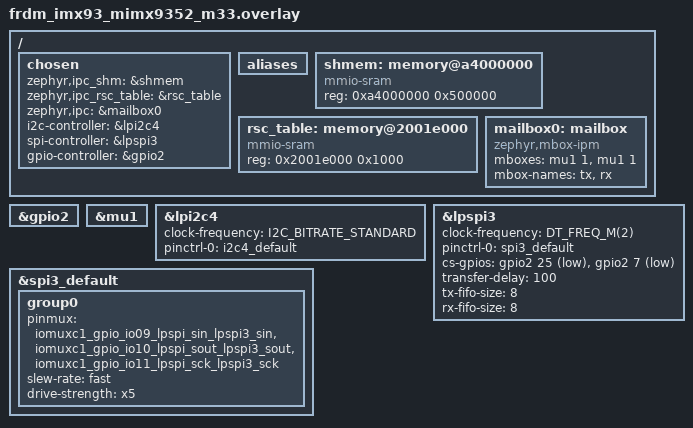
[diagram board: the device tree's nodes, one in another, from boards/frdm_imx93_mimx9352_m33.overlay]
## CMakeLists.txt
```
cmake_minimum_required(VERSION 3.20.0)
# Copyright (c) 2020 STMicroelectronics
#
# SPDX-License-Identifier: Apache-2.0
#

find_package(Zephyr REQUIRED HINTS $ENV{ZEPHYR_BASE})

project(multi_vdev)

target_include_directories(app PRIVATE ${LIBMETAL_INCLUDE_DIR} ${OPENAMP_INCLUDE_DIR} ${PLATFORM_DIR})

target_sources(app
        PRIVATE
        src/main.c
        src/resource_table.c
        src/addr_translation.c
        src/dev_virtio_can.c
        src/dev_virtio_entropy.c
        src/dev_virtio_gpio.c
        src/dev_virtio_i2c.c
        src/dev_virtio_spi.c
)
```

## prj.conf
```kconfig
CONFIG_KERNEL_BIN_NAME="zephyr_multi_vdev"
CONFIG_MAIN_STACK_SIZE=4096
CONFIG_HEAP_MEM_POOL_SIZE=8192

CONFIG_IPM=y
CONFIG_OPENAMP=y
CONFIG_OPENAMP_MASTER=n

CONFIG_GPIO=y
CONFIG_I2C=y
CONFIG_SPI=y
CONFIG_TEST_RANDOM_GENERATOR=y

CONFIG_SHELL=y
CONFIG_LOG=y
```

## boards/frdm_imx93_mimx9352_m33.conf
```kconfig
CONFIG_IPM_MBOX=y
CONFIG_MBOX_INIT_PRIORITY=0
CONFIG_SPI_COMPLETION_TIMEOUT_TOLERANCE=600
```

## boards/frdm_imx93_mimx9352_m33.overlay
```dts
/*
 * Copyright 2025 NXP
 *
 * SPDX-License-Identifier: Apache-2.0
 */

#include <zephyr/dt-bindings/i2c/i2c.h>
#include <zephyr/dt-bindings/gpio/gpio.h>

/ {
	chosen {
		/*
		 * shared memory reserved for the inter-processor communication
		 */
		zephyr,ipc_shm = &shmem;
		zephyr,ipc_rsc_table = &rsc_table;
		zephyr,ipc = &mailbox0;

		i2c-controller = &lpi2c4;
		spi-controller = &lpspi3;
		gpio-controller = &gpio2;
	};

	aliases {
		/delete-property/ led0;
		/delete-property/ led1;
		/delete-property/ sw0;
	};

	/delete-node/ leds;
	/delete-node/ keys;

	shmem: memory@a4000000 {
		compatible = "mmio-sram";
		reg = <0xa4000000 0x500000>;
	};

	rsc_table: memory@2001e000 {
		compatible = "mmio-sram";
		reg = <0x2001e000 0x1000>;
	};

	mailbox0: mailbox {
		compatible = "zephyr,mbox-ipm";
		mboxes = <&mu1 1>, <&mu1 1>;
		mbox-names = "tx", "rx";
		status = "okay";
	};
};

&gpio2 {
	status = "okay";
};

&mu1 {
	status = "okay";
};

&lpi2c4 {
	clock-frequency = <I2C_BITRATE_STANDARD>;
	pinctrl-0 = <&i2c4_default>;
	pinctrl-names = "default";
	status = "okay";
};

&spi3_default {
	// CS lines are driven as GPIOs, remove them from the spi3 pinmuxing
	group0 {
		pinmux = <&iomuxc1_gpio_io09_lpspi_sin_lpspi3_sin>,
			 <&iomuxc1_gpio_io10_lpspi_sout_lpspi3_sout>,
			 <&iomuxc1_gpio_io11_lpspi_sck_lpspi3_sck>;
		slew-rate = "fast";
		drive-strength = "x5";
	};
};

&lpspi3 {
	clock-frequency = <DT_FREQ_M(2)>;
	pinctrl-0 = <&spi3_default>;
	pinctrl-names = "default";
	cs-gpios = <&gpio2 25 GPIO_ACTIVE_LOW>, <&gpio2 7 GPIO_ACTIVE_LOW>;
	transfer-delay = <100>;
	tx-fifo-size = <8>;
	rx-fifo-size = <8>;
	status = "okay";
};
```

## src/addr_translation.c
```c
/*
 * Copyright 2025 NXP
 *
 * SPDX-License-Identifier: Apache-2.0
 */

#include <zephyr/init.h>
#include <zephyr/logging/log.h>

#include "addr_translation.h"

/*
 * Return table of base physical addresses for the I/O region
 * that starts with the specified physical base address (phys)
 */
static inline const struct phys_pages *get_phys_map(metal_phys_addr_t phys)
{
	(void)phys;
	return NULL;
}

static const struct phys_pages *phys_pages;

/**
 * @brief Translates an offset within an I/O region to a physical address.
 *
 * This function first attempts to translate the offset using the driver's
 * physical address map. If no valid mapping is found, it falls back to the
 * device physical address map.
 *
 * @param io Pointer to the I/O region.
 * @param offset Offset within the I/O region.
 *
 * @return physical address if valid, otherwise METAL_BAD_PHYS.
 */
static metal_phys_addr_t translate_offset_to_phys(struct metal_io_region *io,
						  unsigned long offset)
{
	(void)io;
	size_t i;
	metal_phys_addr_t tmp_addr;
	size_t tmp_size;
	unsigned long tmp_offset = 0;

	if (offset > io->size) {
		return METAL_BAD_PHYS;
	}

	for (i = 0; i < phys_pages->no_pages; i++) {
		tmp_addr = phys_pages->map[i].addr;
		tmp_size = phys_pages->map[i].size;
		if ((tmp_offset <= offset) && (offset < tmp_offset + tmp_size)) {
			return tmp_addr + (offset - tmp_offset);
		}
		tmp_offset += tmp_size;
	}

	return METAL_BAD_PHYS;
}

/**
 * @brief Translates a physical address to an offset within an I/O region.
 *
 * This function first attempts to translate the physical address using the
 * driver's address map. If no valid mapping is found, it falls back to the
 * device address map.
 *
 * @param io Pointer to the I/O region.
 * @param phys Physical address to translate.
 *
 * @return offset if valid, otherwise METAL_BAD_OFFSET.
 */
static unsigned long translate_phys_to_offset(struct metal_io_region *io,
					      metal_phys_addr_t phys)
{
	(void)io;
	size_t i;
	metal_phys_addr_t tmp_addr;
	size_t tmp_size;
	unsigned long offset = 0;

	for (i = 0; i < phys_pages->no_pages; i++) {
		tmp_addr = phys_pages->map[i].addr;
		tmp_size = phys_pages->map[i].size;
		if ((tmp_addr <= phys) && (phys < tmp_addr + tmp_size)) {
			offset += (phys - tmp_addr);
			return (offset < io->size ? offset : METAL_BAD_OFFSET);
		}
		offset += tmp_size;
	}

	/* if not found in local addr, search in remote addr */
	offset = 0;
	for (i = 0; i < phys_pages->no_pages; i++) {
		tmp_addr = phys_pages->map[i].remote_addr;
		tmp_size = phys_pages->map[i].size;
		if ((phys >= tmp_addr) && (phys < tmp_addr + tmp_size)) {
			offset += (phys - tmp_addr);
			return (offset < io->size ? offset : METAL_BAD_OFFSET);
		}
		offset += tmp_size;
	}

	return METAL_BAD_OFFSET;
}

/* Address translation operations for OpenAMP */
static const struct metal_io_ops openamp_addr_translation_ops = {
	.phys_to_offset = translate_phys_to_offset,
	.offset_to_phys = translate_offset_to_phys,
};

/**
 * @brief Return generic I/O operations
 *
 * @param	phys	Physical base address of the I/O region
 * @return	metal_io_ops struct
 */
const struct metal_io_ops *addr_translation_get_ops(metal_phys_addr_t phys)
{
	phys_pages = get_phys_map(phys);
	if (!phys_pages) {
		return NULL;
	}

	return &openamp_addr_translation_ops;
}
```

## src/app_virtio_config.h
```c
/*
 * Copyright (c) 2026 Francesco Valla
 *
 * SPDX-License-Identifier: Apache-2.0
 */

#ifndef _APP_VIRTIO_CONFIG_H
#define _APP_VIRTIO_CONFIG_H

#include <zephyr/types.h>

#define V_GPIO_NUM 28

extern const uint8_t v_gpio_names[];
extern const size_t v_gpio_names_len;

#endif // _APP_VIRTIO_CONFIG_H
```

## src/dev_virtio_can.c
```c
/*
 * Virtio CAN device implementation
 *
 * Copyright (C) 2026 Francesco Valla
 *
 * SPDX-License-Identifier: Apache-2.0
 */

#include <metal/alloc.h>
#include <metal/mutex.h>
#include <metal/sleep.h>
#include <metal/sys.h>
#include <metal/utilities.h>

#include <openamp/virtqueue.h>
#include <openamp/remoteproc_virtio.h>

#include <zephyr/kernel.h>
#include <zephyr/device.h>
#include <zephyr/logging/log.h>
#include <zephyr/sys/byteorder.h>

#include "dev_virtio_common.h"
#include "dev_virtio_can.h"

#include "virtio_can.h"

LOG_MODULE_REGISTER(virtio_can, CONFIG_LOG_DEFAULT_LEVEL);

/**
 * @internal
 *
 * @brief TX callback function.
 *
 * @param vq	Pointer to virtqueue on which TX request is received
 */
static void dev_virtio_can_tx_callback(struct virtqueue *vq)
{
	struct virtio_device *vdev = vq->vq_dev;
	struct dev_virtio_can_device *vcdev = vdev->priv;
	const struct virtio_can_tx_out *tx_out = NULL;
	struct virtio_can_tx_in *tx_in = NULL;
	void *buf_out = NULL, *buf_in = NULL;
	uint16_t idx_out, idx_in;
	uint32_t len_out, len_in;
	int ret;

	while (1) {
		/* Process the received data from remote node */
		metal_mutex_acquire(&vcdev->lock);

		buf_out = virtqueue_get_first_avail_buffer(vq, &idx_out, &len_out);

		/* No more filled rx buffers */
		if (!buf_out) {
			metal_mutex_release(&vcdev->lock);
			break;
		}

		buf_in = virtqueue_get_next_avail_buffer(vq, idx_out, &idx_in, &len_in);
		if (!buf_in) {
			virtqueue_add_consumed_buffer(vq, idx_out, 0);
			virtqueue_kick(vq);
			metal_mutex_release(&vcdev->lock);
			metal_log(METAL_LOG_ERROR, "no response buffer");
			break;
		}

		metal_mutex_release(&vcdev->lock);

		if (len_out < sizeof(struct virtio_can_tx_out)) {
			LOG_ERR("invalid tx_out length %u", len_out);
		} else if (len_in < sizeof(struct virtio_can_tx_in)) {
			LOG_ERR("invalid tx_in length %u", len_in);
		} else {
			uint16_t msg_type;

			/* Invalidate cache before using buffer */
			BUFFER_INVALIDATE(buf_out, len_out);

			tx_out = (struct virtio_can_tx_out *)buf_out;
			tx_in = (struct virtio_can_tx_in *)buf_in;

			msg_type = sys_get_le16((const uint8_t *)&tx_out->msg_type);

			/* Set error as default response */
			tx_in->result = VIRTIO_CAN_RESULT_NOT_OK;

			if (unlikely(msg_type != VIRTIO_CAN_TX)) {
				LOG_WRN("Not a CAN TX message!");
			} else if (unlikely(!vcdev->callbacks->send)) {
				LOG_ERR("No send callback");
			} else {
				uint16_t length = sys_get_le16((const uint8_t *)&tx_out->length);
				uint32_t flags = sys_get_le32((const uint8_t *)&tx_out->flags);
				uint32_t can_id = sys_get_le32((const uint8_t *)&tx_out->can_id);

				ret = vcdev->callbacks->send(can_id, length, tx_out->sdu,
							     !!(flags & VIRTIO_CAN_FLAGS_EXTENDED),
							     !!(flags & VIRTIO_CAN_FLAGS_FD),
							     !!(flags & VIRTIO_CAN_FLAGS_RTR));
				if (ret == 0) {
					tx_in->result = VIRTIO_CAN_RESULT_OK;
				} else {
					LOG_ERR("send callback failed with %d", ret);
					tx_in->result = VIRTIO_CAN_RESULT_NOT_OK;
				}
			}

			BUFFER_FLUSH(buf_in, len_in);
		}

		metal_mutex_acquire(&vcdev->lock);

		ret = virtqueue_add_consumed_buffer(vq, idx_out, len_in);
		if (ret != 0)
			LOG_ERR("Add consumed buffer failed: %d", ret);

		virtqueue_kick(vq);

		metal_mutex_release(&vcdev->lock);
	}
}

/**
 * @internal
 *
 * @brief RX callback function.
 *
 * @param vq	Pointer to virtqueue on which RX request is received
 */
static void dev_virtio_can_rx_callback(struct virtqueue *vq)
{

}

/**
 * @internal
 *
 * @brief Control callback function.
 *
 * @param vq	Pointer to virtqueue on which control request is received
 */
static void dev_virtio_can_control_callback(struct virtqueue *vq)
{
	struct virtio_device *vdev = vq->vq_dev;
	struct dev_virtio_can_device *vcdev = vdev->priv;
	const struct virtio_can_control_out *ctrl_out = NULL;
	struct virtio_can_control_in *ctrl_in = NULL;
	void *buf_out = NULL, *buf_in = NULL;
	uint16_t idx_out, idx_in;
	uint32_t len_out, len_in;
	int ret;

	while (1) {
		/* Process the received data from remote node */
		metal_mutex_acquire(&vcdev->lock);

		buf_out = virtqueue_get_first_avail_buffer(vq, &idx_out, &len_out);

		/* No more filled rx buffers */
		if (!buf_out) {
			metal_mutex_release(&vcdev->lock);
			break;
		}

		buf_in = virtqueue_get_next_avail_buffer(vq, idx_out, &idx_in, &len_in);
		if (!buf_in) {
			virtqueue_add_consumed_buffer(vq, idx_out, 0);
			virtqueue_kick(vq);
			metal_mutex_release(&vcdev->lock);
			metal_log(METAL_LOG_ERROR, "no response buffer");
			break;
		}

		metal_mutex_release(&vcdev->lock);

		if (len_out < sizeof(struct virtio_can_control_out)) {
			LOG_ERR("invalid ctrl_out length %u", len_out);
		} else if (len_in < sizeof(struct virtio_can_control_in)) {
			LOG_ERR("invalid ctrl_in length %u", len_in);
		} else {
			uint16_t msg_type;

			/* Invalidate cache before using buffer */
			BUFFER_INVALIDATE(buf_out, len_out);

			ctrl_out = (struct virtio_can_control_out *)buf_out;
			ctrl_in = (struct virtio_can_control_in *)buf_in;

			msg_type = sys_get_le16((const uint8_t *)&ctrl_out->msg_type);

			/* Set error as default response */
			ctrl_in->result = VIRTIO_CAN_RESULT_NOT_OK;

			switch (msg_type) {
			case VIRTIO_CAN_SET_CTRL_MODE_START:
				LOG_DBG("START");

				if (unlikely(!vcdev->callbacks->set_started)) {
					LOG_ERR("No set_started callback");
					break;
				}

				ret = vcdev->callbacks->set_started(true);
				if (ret == 0) {
					ctrl_in->result = VIRTIO_CAN_RESULT_OK;
				} else {
					LOG_ERR("set_started(true) callback failed with %d", ret);
					ctrl_in->result = VIRTIO_CAN_RESULT_NOT_OK;
				}
				break;
			case VIRTIO_CAN_SET_CTRL_MODE_STOP:
				LOG_DBG("STOP");

				if (!vcdev->callbacks->set_started) {
					LOG_ERR("No set_started callback");
					break;
				}

				ret = vcdev->callbacks->set_started(false);
				if (ret == 0) {
					ctrl_in->result = VIRTIO_CAN_RESULT_OK;
				} else {
					LOG_ERR("set_started(false) callback failed with %d", ret);
					ctrl_in->result = VIRTIO_CAN_RESULT_NOT_OK;
				}
				break;
			default:
				LOG_ERR("Unknown control type %u", msg_type);
				break;
			}

			BUFFER_FLUSH(buf_in, len_in);
		}

		metal_mutex_acquire(&vcdev->lock);

		ret = virtqueue_add_consumed_buffer(vq, idx_out, len_in);
		if (ret != 0)
			LOG_ERR("Add consumed buffer failed: %d", ret);

		virtqueue_kick(vq);

		metal_mutex_release(&vcdev->lock);
	}
}

int dev_virtio_can_receive(struct dev_virtio_can_device *vcdev, uint32_t id,
			   uint16_t length, const uint8_t *sdu, bool extended,
			   bool fd, bool rtr)
{
	struct virtqueue *vq = vcdev->vq_rx;
	struct virtio_can_rx *rx = NULL;
	size_t req_len;
	void *buf = NULL;
	uint16_t idx;
	uint32_t len;
	int ret;

	/* Process the received data from remote node */
	metal_mutex_acquire(&vcdev->lock);

	buf = virtqueue_get_first_avail_buffer(vq, &idx, &len);

	/* No buffer available */
	if (!buf) {
		metal_mutex_release(&vcdev->lock);
		return -1;
	}

	metal_mutex_release(&vcdev->lock);

	req_len = sizeof(struct virtio_can_rx) + length;
	if (len < req_len) {
		LOG_ERR("TX buffer too small");
		req_len = 0;
	} else {
		uint32_t flags = 0;

		/* Invalidate cache before using buffer */
		BUFFER_INVALIDATE(buf, len);

		rx = (struct virtio_can_rx *)buf;

		sys_put_le16(VIRTIO_CAN_RX, (uint8_t *)&rx->msg_type);
		sys_put_le32(id, (uint8_t *)&rx->can_id);
		sys_put_le16(length, (uint8_t *)&rx->length);

		if (extended)
			flags |= VIRTIO_CAN_FLAGS_EXTENDED;

		if (fd)
			flags |= VIRTIO_CAN_FLAGS_FD;

		if (rtr)
			flags |= VIRTIO_CAN_FLAGS_RTR;

		sys_put_le32(flags, (uint8_t *)&rx->flags);

		memcpy(rx->sdu, sdu, length);

		BUFFER_FLUSH(buf_in, req_len);
	}

	metal_mutex_acquire(&vcdev->lock);

	ret = virtqueue_add_consumed_buffer(vq, idx, req_len);
	if (ret != 0)
		LOG_ERR("Add consumed buffer failed: %d", ret);

	virtqueue_kick(vq);

	metal_mutex_release(&vcdev->lock);

	return ret;
}

int dev_virtio_can_init_vdev(struct dev_virtio_can_device *vcdev,
			     struct virtio_device *vdev,
			     const dev_virtio_can_cb_set *cb_set,
			     struct metal_io_region *shm_io)
{
	const char *vq_names[VIRTIO_CAN_VRINGS];
	vq_callback callbacks[VIRTIO_CAN_VRINGS];
	int status;

	if (!vcdev || !vdev || !cb_set || !shm_io)
		return -EINVAL;

	if (VIRTIO_ROLE_IS_DRIVER(vdev)) {
		return -ENOTSUP;
	}

	memset(vcdev, 0, sizeof(*vcdev));

	vcdev->vdev = vdev;
	vcdev->callbacks = cb_set;

	vdev->priv = vcdev;

	metal_mutex_init(&vcdev->lock);

	vq_names[0] = "txq";
	callbacks[0] = dev_virtio_can_tx_callback;

	vq_names[1] = "rxq";
	callbacks[1] = dev_virtio_can_rx_callback;

	vq_names[2] = "controlq";
	callbacks[2] = dev_virtio_can_control_callback;

	/* Create virtqueues for remote device */
	status = virtio_create_virtqueues(vdev, 0, VIRTIO_CAN_VRINGS,
					  vq_names, callbacks, NULL);
	if (status != 0)
		return status;

	vcdev->vq_tx = vdev->vrings_info[0].vq;
	vcdev->vq_tx->shm_io = shm_io;

	vcdev->vq_rx = vdev->vrings_info[1].vq;
	vcdev->vq_rx->shm_io = shm_io;

	vcdev->vq_control = vdev->vrings_info[2].vq;
	vcdev->vq_control->shm_io = shm_io;

	return 0;
}

void dev_virtio_can_deinit_vdev(struct dev_virtio_can_device *vcdev)
{
	if (vcdev) {
		vcdev->vq_tx = NULL;
		vcdev->vq_rx = NULL;
		vcdev->vq_control = NULL;

		virtio_delete_virtqueues(vcdev->vdev);
		vcdev->vdev = NULL;

		metal_mutex_deinit(&vcdev->lock);
	}
}
```

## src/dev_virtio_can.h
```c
/*
 * Virtio CAN device implementation
 *
 * Copyright (C) 2026 Francesco Valla
 *
 * SPDX-License-Identifier: Apache-2.0
 */

#ifndef _DEV_VIRTIO_CAN_H_
#define _DEV_VIRTIO_CAN_H_

#include <metal/io.h>
#include <metal/mutex.h>
#include <metal/cache.h>

#include <openamp/virtio.h>

#define VIRTIO_CAN_VRINGS	3

#if defined __cplusplus
extern "C" {
#endif

/** @brief Callback handlers for CAN requests */
typedef struct {
	/** Start or stop CAN communication */
	int (*set_started)(bool start);
	/** Send CAN message */
	int (*send)(uint32_t id, uint16_t length, const uint8_t *sdu,
		    bool extended, bool fd, bool rtr);
} dev_virtio_can_cb_set;

/** @brief Representation of a CAN device based on virtio */
struct dev_virtio_can_device {
	/** Pointer to the virtio device */
	struct virtio_device *vdev;

	/** Pointer to TX virtqueue */
	struct virtqueue *vq_tx;

	/** Pointer to RX virtqueue */
	struct virtqueue *vq_rx;

	/** Pointer to control virtqueue */
	struct virtqueue *vq_control;

	/** Callback handlers */
	const dev_virtio_can_cb_set *callbacks;

	/** Mutex for callbacks */
	metal_mutex_t lock;
};

/**
 * @brief Initialize virtio CAN device
 *
 * @param vcdev		Pointer to the CAN virtio device
 * @param vdev		Pointer to the virtio device
 * @param callbacks	Pointer to set of callbacks
 * @param shm_io	Pointer to the share memory I/O region.
 *
 * @return Status of function execution
 */
int dev_virtio_can_init_vdev(struct dev_virtio_can_device *vcdev,
			     struct virtio_device *vdev,
			     const dev_virtio_can_cb_set *callbacks,
			     struct metal_io_region *shm_io);

/**
 * @brief Deinitialize CAN virtio device
 *
 * @param vcdev	Pointer to the CAN virtio device
 */
void dev_virtio_can_deinit_vdev(struct dev_virtio_can_device *vcdev);

/**
 * @brief Receive CAN message (driver point-of-view)
 *
 * @param vcdev		Pointer to the CAN virtio device
 * @param id		CAN ID
 * @param length	Payload length
 * @param sdu		Payload buffer
 * @param extended	CAN ID is extended
 * @param fd		Wheter the CAN message is a CAN-FD one or not
 * @param rtr		Wheter the CAN message is a RTR one or not
 *
 * @return 0 on success, a negative number on error
 */
int dev_virtio_can_receive(struct dev_virtio_can_device *vcdev, uint32_t id,
			    uint16_t length, const uint8_t *sdu, bool extended,
			    bool fd, bool rtr);

#if defined __cplusplus
}
#endif

#endif	/* _DEV_VIRTIO_CAN_H_ */
```

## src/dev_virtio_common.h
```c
/*
 * Virtio device common utilities
 *
 * Copyright (C) 2026 Francesco Valla
 *
 * SPDX-License-Identifier: Apache-2.0
 */

#ifndef _DEV_VIRTIO_COMMON_H_
#define _DEV_VIRTIO_COMMON_H_

#if defined(CONFIG_OPENAMP_WITH_DCACHE)
#define BUFFER_FLUSH(x, s)		metal_cache_flush(x, s)
#define BUFFER_INVALIDATE(x, s)		metal_cache_invalidate(x, s)
#else
#define BUFFER_FLUSH(x, s)		do { } while (0)
#define BUFFER_INVALIDATE(x, s)		do { } while (0)
#endif /* OPENAMP_WITH_DCACHE */

#endif	/* _DEV_VIRTIO_COMMON_H_ */
```

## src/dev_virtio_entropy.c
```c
/*
 * Virtio entropy device implementation
 *
 * Copyright (C) 2026 Francesco Valla
 *
 * SPDX-License-Identifier: Apache-2.0
 */

#include <metal/alloc.h>
#include <metal/mutex.h>
#include <metal/sleep.h>
#include <metal/sys.h>
#include <metal/utilities.h>

#include <zephyr/kernel.h>
#include <zephyr/device.h>
#include <zephyr/logging/log.h>

#include <openamp/virtqueue.h>
#include <openamp/remoteproc_virtio.h>

#include "dev_virtio_common.h"
#include "dev_virtio_entropy.h"

LOG_MODULE_REGISTER(virtio_entropy, CONFIG_LOG_DEFAULT_LEVEL);

/**
 * @internal
 *
 * @brief Request callback function.
 *
 * @param vq	Pointer to virtqueue on which request is received
 */
static void dev_virtio_entropy_req_callback(struct virtqueue *vq)
{
	struct virtio_device *vdev = vq->vq_dev;
	struct dev_virtio_entropy_device *vedev = vdev->priv;
	uint32_t len;
	uint16_t idx;
	void *buf = NULL;
	int ret;

	while (1) {
		/* Process the received data from remote node */
		metal_mutex_acquire(&vedev->lock);

		buf = virtqueue_get_first_avail_buffer(vq, &idx, &len);

		/* No more filled rx buffers */
		if (!buf) {
			metal_mutex_release(&vedev->lock);
			break;
		}

		/* Invalidate cache before using buffer */
		BUFFER_INVALIDATE(buf, len);

		metal_mutex_release(&vedev->lock);

		if (vedev->entropy_cb) {
			vedev->entropy_cb(buf, &len);
		}

		metal_mutex_acquire(&vedev->lock);

		BUFFER_FLUSH(buf, len);
		
		ret = virtqueue_add_consumed_buffer(vq, idx, len);
		if (ret != 0)
			LOG_ERR("Add consumed buffer failed: %d", ret);

		virtqueue_kick(vq);

		metal_mutex_release(&vedev->lock);
	}
}

int dev_virtio_entropy_init_vdev(struct dev_virtio_entropy_device *vedev,
				 struct virtio_device *vdev,
				 dev_virtio_entropy_cb entropy_cb,
				 struct metal_io_region *shm_io)
{
	const char *vq_names[VIRTIO_ENTROPY_VRINGS];
	vq_callback callbacks[VIRTIO_ENTROPY_VRINGS];
	int status;

	if (!vedev || !vdev || !shm_io)
		return -EINVAL;

	if (VIRTIO_ROLE_IS_DRIVER(vdev)) {
		return -ENOTSUP;
	}

	memset(vedev, 0, sizeof(*vedev));

	vedev->vdev = vdev;
	vdev->priv = vedev;
	vedev->entropy_cb = entropy_cb;

	metal_mutex_init(&vedev->lock);

	vq_names[0] = "requestq";
	callbacks[0] = dev_virtio_entropy_req_callback;

	/* Create virtqueues for remote device */
	status = virtio_create_virtqueues(vdev, 0, VIRTIO_ENTROPY_VRINGS,
					  vq_names, callbacks, NULL);
	if (status != 0)
		return status;

	vedev->vq = vdev->vrings_info[0].vq;
	vedev->vq->shm_io = shm_io;

	return 0;
}

void dev_virtio_entropy_deinit_vdev(struct dev_virtio_entropy_device *vedev)
{
	if (vedev) {
		vedev->vq = NULL;

		virtio_delete_virtqueues(vedev->vdev);
		vedev->vdev = NULL;

		metal_mutex_deinit(&vedev->lock);
	}
}
```

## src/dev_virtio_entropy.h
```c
/*
 * Virtio entropy device implementation
 *
 * Copyright (C) 2026 Francesco Valla
 *
 * SPDX-License-Identifier: Apache-2.0
 */

#ifndef _DEV_VIRTIO_ENTROPY_H_
#define _DEV_VIRTIO_ENTROPY_H_

#include <metal/io.h>
#include <metal/mutex.h>
#include <metal/cache.h>
#include <openamp/virtio.h>

#define VIRTIO_ENTROPY_VRINGS	1

#if defined __cplusplus
extern "C" {
#endif

/* Callback handler for entropy request */
typedef void (*dev_virtio_entropy_cb)(uint8_t *data, uint32_t *len);

/** @brief Representation of a entropy device based on virtio */
struct dev_virtio_entropy_device {
	/** Pointer to the virtio device */
	struct virtio_device *vdev;

	/** Pointer to virtqueue */
	struct virtqueue *vq;

	/** Callback handler for entropy request */
	dev_virtio_entropy_cb entropy_cb;

	/** Mutex for callbacks */
	metal_mutex_t lock;
};

/**
 * @brief Initialize virtio entropy device
 *
 * @param vedev		Pointer to the entropy virtio device
 * @param vdev		Pointer to the virtio device
 * @param entropy_cb	Callback handler for entropy request.
 * @param shm_io	Pointer to the share memory I/O region.
 *
 * @return Status of function execution
 */
int dev_virtio_entropy_init_vdev(struct dev_virtio_entropy_device *vedev,
				 struct virtio_device *vdev,
				 dev_virtio_entropy_cb entropy_cb,
				 struct metal_io_region *shm_io);

/**
 * @brief Deinitialize entropy virtio device
 *
 * @param vedev	Pointer to the entropy virtio device
 */
void dev_virtio_entropy_deinit_vdev(struct dev_virtio_entropy_device *vedev);

#if defined __cplusplus
}
#endif

#endif	/* _DEV_VIRTIO_ENTROPY_H_ */
```

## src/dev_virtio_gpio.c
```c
/*
 * Virtio GPIO device implementation
 *
 * Copyright (C) 2026 Francesco Valla
 *
 * SPDX-License-Identifier: Apache-2.0
 */

#include <metal/alloc.h>
#include <metal/mutex.h>
#include <metal/sleep.h>
#include <metal/sys.h>
#include <metal/utilities.h>

#include <openamp/virtqueue.h>
#include <openamp/remoteproc_virtio.h>

#include <zephyr/kernel.h>
#include <zephyr/device.h>
#include <zephyr/logging/log.h>
#include <zephyr/sys/byteorder.h>

#include "dev_virtio_common.h"
#include "dev_virtio_gpio.h"

#include "virtio_gpio.h"

LOG_MODULE_REGISTER(virtio_gpio, CONFIG_LOG_DEFAULT_LEVEL);

/**
 * @internal
 *
 * @brief Request callback function.
 *
 * @param vq	Pointer to virtqueue on which request is received
 */
static void dev_virtio_gpio_req_callback(struct virtqueue *vq)
{
	struct virtio_device *vdev = vq->vq_dev;
	struct dev_virtio_gpio_device *vgdev = vdev->priv;
	const struct virtio_gpio_request *gpio_req = NULL;
	void *buf_rq = NULL, *buf_rs = NULL;
	uint16_t idx_rq, idx_rs;
	uint32_t len_rq, len_rs;
	int ret;

	while (1) {
		/* Process the received data from remote node */
		metal_mutex_acquire(&vgdev->lock);

		buf_rq = virtqueue_get_first_avail_buffer(vq, &idx_rq, &len_rq);

		/* No more filled rx buffers */
		if (!buf_rq) {
			metal_mutex_release(&vgdev->lock);
			break;
		}

		buf_rs = virtqueue_get_next_avail_buffer(vq, idx_rq, &idx_rs, &len_rs);
		if (!buf_rs) {
			virtqueue_add_consumed_buffer(vq, idx_rq, 0);
			virtqueue_kick(vq);
			metal_mutex_release(&vgdev->lock);
			metal_log(METAL_LOG_ERROR, "no response buffer");
			break;
		}

		metal_mutex_release(&vgdev->lock);

		if (len_rq < sizeof(struct virtio_gpio_request)) {
			LOG_ERR("invalid request length %u", len_rq);
		} else if (len_rs < sizeof(struct virtio_gpio_response)) {
			LOG_ERR("invalid response length %u", len_rs);
		} else {
			uint16_t type, gpio;
			uint32_t value;

			/* Invalidate cache before using buffer */
			BUFFER_INVALIDATE(buf_rq, len_rq);

			gpio_req = (struct virtio_gpio_request *)buf_rq;

			type = sys_get_le16((const uint8_t *)&gpio_req->type);
			gpio = sys_get_le16((const uint8_t *)&gpio_req->gpio);
			value = sys_get_le32((const uint8_t *)&gpio_req->value);

			/* Set error as default response */
			*(uint8_t *)buf_rs = VIRTIO_GPIO_STATUS_ERR;

			switch (type) {
			case VIRTIO_GPIO_MSG_GET_NAMES:
				LOG_DBG("GET_NAMES");
				if (vgdev->callbacks->get_names != NULL) {
					struct virtio_gpio_response_get_names *res =
						(struct virtio_gpio_response_get_names *)buf_rs;

					ret = vgdev->callbacks->get_names(res->value, len_rs - sizeof(uint8_t));
					if (ret == 0)
						res->status = VIRTIO_GPIO_STATUS_OK;
					else {
						LOG_ERR("get_names callback failed with %d", ret);
						res->status = VIRTIO_GPIO_STATUS_ERR;
					}
				} else {
					LOG_ERR("No get_names callback");
				}
				break;
			case VIRTIO_GPIO_MSG_GET_DIRECTION:
				LOG_DBG("GET_DIRECTION(%u)", gpio);
				if (vgdev->callbacks->get_direction != NULL) {
					struct virtio_gpio_response *res =
						(struct virtio_gpio_response *)buf_rs;
					dev_virtio_gpio_direction_t direction;

					ret = vgdev->callbacks->get_direction(gpio, &direction);
					if (ret == 0) {
						switch (direction) {
						case DEV_VIRTIO_GPIO_DIRECTION_NONE:
							res->value = VIRTIO_GPIO_DIRECTION_NONE;
							res->status = VIRTIO_GPIO_STATUS_OK;
							break;
						case DEV_VIRTIO_GPIO_DIRECTION_OUT:
							res->value = VIRTIO_GPIO_DIRECTION_OUT;
							res->status = VIRTIO_GPIO_STATUS_OK;
							break;
						case DEV_VIRTIO_GPIO_DIRECTION_IN:
							res->value = VIRTIO_GPIO_DIRECTION_IN;
							res->status = VIRTIO_GPIO_STATUS_OK;
							break;
						default:
							LOG_ERR("Invalid direction %u", direction);
							res->status = VIRTIO_GPIO_STATUS_ERR;
							break;
						}
					} else {
						LOG_ERR("get_direction callback failed with %d", ret);
						res->status = VIRTIO_GPIO_STATUS_ERR;
					}
				} else {
					LOG_ERR("No get_direction callback");
				}
				break;
			case VIRTIO_GPIO_MSG_SET_DIRECTION:
				LOG_DBG("SET_DIRECTION(%u, %u)", gpio, value);
				if (vgdev->callbacks->set_direction != NULL) {
					struct virtio_gpio_response *res =
						(struct virtio_gpio_response *)buf_rs;

					switch (value) {
					case VIRTIO_GPIO_DIRECTION_NONE:
						ret = vgdev->callbacks->set_direction(gpio, DEV_VIRTIO_GPIO_DIRECTION_NONE);
						break;
					case VIRTIO_GPIO_DIRECTION_OUT:
						ret = vgdev->callbacks->set_direction(gpio, DEV_VIRTIO_GPIO_DIRECTION_OUT);
						break;
					case VIRTIO_GPIO_DIRECTION_IN:
						ret = vgdev->callbacks->set_direction(gpio, DEV_VIRTIO_GPIO_DIRECTION_IN);
						break;
					default:
						LOG_ERR("Invalid direction %u", value);
						ret = -1;
						break;
					}

					if (ret == 0) {
						res->value = value;
						res->status = VIRTIO_GPIO_STATUS_OK;
					} else {
						LOG_ERR("set_direction callback failed with %d", ret);
						res->status = VIRTIO_GPIO_STATUS_ERR;
					}
				} else {
					LOG_ERR("No set_direction callback");
				}
				break;
			case VIRTIO_GPIO_MSG_GET_VALUE:
				LOG_DBG("GET_VALUE(%u)", gpio);
				if (vgdev->callbacks->get_value != NULL) {
					struct virtio_gpio_response *res =
						(struct virtio_gpio_response *)buf_rs;
					unsigned int tmp;

					ret = vgdev->callbacks->get_value(gpio, &tmp);
					if (ret == 0) {
						res->status = VIRTIO_GPIO_STATUS_OK;
						res->value = !!tmp;
					} else {
						LOG_ERR("get_value callback failed with %d", ret);
						res->status = VIRTIO_GPIO_STATUS_ERR;
					}
				} else {
					LOG_ERR("No get_value callback");
				}
				break;
			case VIRTIO_GPIO_MSG_SET_VALUE:
				LOG_DBG("SET_VALUE(%u, %u)", gpio, value);
				if (vgdev->callbacks->set_value != NULL) {
					struct virtio_gpio_response *res =
						(struct virtio_gpio_response *)buf_rs;

					ret = vgdev->callbacks->set_value(gpio, value);
					if (ret == 0) {
						res->status = VIRTIO_GPIO_STATUS_OK;
						res->value = value;
					} else {
						LOG_ERR("set_value callback failed with %d", ret);
						res->status = VIRTIO_GPIO_STATUS_ERR;
					}
				}
				break;
			case VIRTIO_GPIO_MSG_IRQ_TYPE:
				LOG_DBG("IRQ_TYPE(%u, %u)", gpio, value);
				if (vgdev->callbacks->set_irq_type != NULL) {
					struct virtio_gpio_response *res =
						(struct virtio_gpio_response *)buf_rs;

					switch (value) {
					case VIRTIO_GPIO_IRQ_TYPE_NONE:
						ret = vgdev->callbacks->set_irq_type(gpio, DEV_VIRTIO_GPIO_IRQ_TYPE_NONE);
						break;
					case VIRTIO_GPIO_IRQ_TYPE_EDGE_RISING:
						ret = vgdev->callbacks->set_irq_type(gpio, DEV_VIRTIO_GPIO_IRQ_TYPE_EDGE_RISING);
						break;
					case VIRTIO_GPIO_IRQ_TYPE_EDGE_FALLING:
						ret = vgdev->callbacks->set_irq_type(gpio, DEV_VIRTIO_GPIO_IRQ_TYPE_EDGE_FALLING);
						break;
					case VIRTIO_GPIO_IRQ_TYPE_EDGE_BOTH:
						ret = vgdev->callbacks->set_irq_type(gpio, DEV_VIRTIO_GPIO_IRQ_TYPE_EDGE_BOTH);
						break;
					case VIRTIO_GPIO_IRQ_TYPE_LEVEL_HIGH:
						ret = vgdev->callbacks->set_irq_type(gpio, DEV_VIRTIO_GPIO_IRQ_TYPE_LEVEL_HIGH);
						break;
					case VIRTIO_GPIO_IRQ_TYPE_LEVEL_LOW:
						ret = vgdev->callbacks->set_irq_type(gpio, DEV_VIRTIO_GPIO_IRQ_TYPE_LEVEL_LOW);
						break;
					default:
						LOG_ERR("Invalid IRQ type %u", value);
						ret = -1;
						break;
					}

					if (ret == 0) {
						res->status = VIRTIO_GPIO_STATUS_OK;
						res->value = value;
					} else {
						LOG_ERR("set_irq_type callback failed with %d", ret);
						res->status = VIRTIO_GPIO_STATUS_ERR;
					}
				} else {
					LOG_ERR("No set_irq_type callback");
				}
				break;
			default:
				LOG_ERR("Unknown request type %u", type);
				break;
			}

			BUFFER_FLUSH(buf_rs, len_rs);
		}

		metal_mutex_acquire(&vgdev->lock);

		ret = virtqueue_add_consumed_buffer(vq, idx_rq, len_rs);
		if (ret != 0)
			LOG_ERR("Add consumed buffer failed: %d", ret);

		virtqueue_kick(vq);

		metal_mutex_release(&vgdev->lock);
	}
}

static void dev_virtio_gpio_ev_callback(struct virtqueue *vq)
{
	struct virtio_device *vdev = vq->vq_dev;
	struct dev_virtio_gpio_device *vgdev = vdev->priv;
	const struct virtio_gpio_irq_request *irq_req = NULL;
	struct virtio_gpio_irq_response *irq_resp = NULL;
	void *buf_rq = NULL, *buf_rs = NULL;
	uint16_t idx_rq, idx_rs;
	uint32_t len_rq, len_rs;
	int ret;

	while (1) {
		/* Process the received data from remote node */
		metal_mutex_acquire(&vgdev->lock);

		buf_rq = virtqueue_get_first_avail_buffer(vq, &idx_rq, &len_rq);

		/* No more filled req buffers */
		if (!buf_rq) {
			metal_mutex_release(&vgdev->lock);
			break;
		}

		buf_rs = virtqueue_get_next_avail_buffer(vq, idx_rq, &idx_rs, &len_rs);
		if (!buf_rs) {
			virtqueue_add_consumed_buffer(vq, idx_rq, 0);
			virtqueue_kick(vq);
			metal_mutex_release(&vgdev->lock);
			metal_log(METAL_LOG_ERROR, "no response buffer");
			break;
		}

		metal_mutex_release(&vgdev->lock);

		if (len_rq < sizeof(struct virtio_gpio_irq_request)) {
			LOG_ERR("invalid request length %u", len_rq);
			ret = -1;
		} else if (len_rs < sizeof(struct virtio_gpio_irq_response)) {
			LOG_ERR("invalid response length %u", len_rs);
			ret = -1;
		} else {
			uint16_t gpio;

			/* Invalidate cache before using buffer */
			BUFFER_INVALIDATE(buf_rq, len_rq);

			irq_req = (struct virtio_gpio_irq_request *)buf_rq;
			irq_resp = (struct virtio_gpio_irq_response *)buf_rs;

			gpio = sys_get_le16((const uint8_t *)&irq_req->gpio);

			LOG_DBG("IRQ_REQ(%u)", gpio);
			if (vgdev->callbacks->unmask_irq != NULL) {
				ret = vgdev->callbacks->unmask_irq(gpio,
								   (void *)irq_resp, idx_rq);
				if (ret != 0) {
					LOG_ERR("unmask_irq callback failed with %d", ret);
				}
			} else {
				LOG_ERR("No unmask_irq callback");
				ret = -1;
			}
		}

		// An immediate response is sent only in case of error
		if (ret != 0) {
			irq_resp->status = VIRTIO_GPIO_IRQ_STATUS_INVALID;
			BUFFER_FLUSH(buf_rs, len_rs);

			metal_mutex_acquire(&vgdev->lock);

			ret = virtqueue_add_consumed_buffer(vq, idx_rq, len_rs);
			if (ret != 0)
				LOG_ERR("Add consumed buffer failed: %d", ret);

			virtqueue_kick(vq);

			metal_mutex_release(&vgdev->lock);
		}
	}
}

void dev_virtio_send_irq(struct dev_virtio_gpio_device *vgdev,
			 unsigned int gpio, void *ctx, unsigned int ctx2)
{
	struct virtio_gpio_irq_response *irq_resp =
		(struct virtio_gpio_irq_response *)ctx;
	uint32_t len_rs = sizeof(struct virtio_gpio_irq_response);
	uint16_t idx = ctx2;
	int ret;

	// Sanity check
	if (!irq_resp) {
		LOG_ERR("Invalid IRQ context!");
		return;
	}

	irq_resp->status = VIRTIO_GPIO_IRQ_STATUS_VALID;

	BUFFER_FLUSH(irq_resp, len_rs);

	metal_mutex_acquire(&vgdev->lock);

	ret = virtqueue_add_consumed_buffer(vgdev->vq_event, idx, len_rs);
	if (ret != 0)
		LOG_ERR("Add consumed buffer failed: %d", ret);

	virtqueue_kick(vgdev->vq_event);

	metal_mutex_release(&vgdev->lock);
}

int dev_virtio_gpio_init_vdev(struct dev_virtio_gpio_device *vgdev,
			      struct virtio_device *vdev,
			      const dev_virtio_gpio_cb_set *cb_set,
			      struct metal_io_region *shm_io)
{
	const char *vq_names[VIRTIO_GPIO_VRINGS];
	vq_callback callbacks[VIRTIO_GPIO_VRINGS];
	int status;

	if (!vgdev || !vdev || !cb_set || !shm_io)
		return -EINVAL;

	if (VIRTIO_ROLE_IS_DRIVER(vdev)) {
		return -ENOTSUP;
	}

	memset(vgdev, 0, sizeof(*vgdev));

	vgdev->vdev = vdev;
	vgdev->callbacks = cb_set;

	vdev->priv = vgdev;

	metal_mutex_init(&vgdev->lock);

	vq_names[0] = "requestq";
	callbacks[0] = dev_virtio_gpio_req_callback;

	vq_names[1] = "eventq";
	callbacks[1] = dev_virtio_gpio_ev_callback;

	/* Create virtqueues for remote device */
	status = virtio_create_virtqueues(vdev, 0, VIRTIO_GPIO_VRINGS,
					  vq_names, callbacks, NULL);
	if (status != 0)
		return status;

	vgdev->vq_request = vdev->vrings_info[0].vq;
	vgdev->vq_request->shm_io = shm_io;

	vgdev->vq_event = vdev->vrings_info[1].vq;
	vgdev->vq_event->shm_io = shm_io;

	return 0;
}

void dev_virtio_gpio_deinit_vdev(struct dev_virtio_gpio_device *vgdev)
{
	if (vgdev) {
		vgdev->vq_request = NULL;
		vgdev->vq_event = NULL;

		virtio_delete_virtqueues(vgdev->vdev);
		vgdev->vdev = NULL;

		metal_mutex_deinit(&vgdev->lock);
	}
}
```

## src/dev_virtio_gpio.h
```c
/*
 * Virtio GPIO device implementation
 *
 * Copyright (C) 2026 Francesco Valla
 *
 * SPDX-License-Identifier: Apache-2.0
 */

#ifndef _DEV_VIRTIO_GPIO_H_
#define _DEV_VIRTIO_GPIO_H_

#include <metal/io.h>
#include <metal/mutex.h>
#include <metal/cache.h>

#include <openamp/virtio.h>

#define VIRTIO_GPIO_VRINGS	2

#if defined __cplusplus
extern "C" {
#endif

typedef enum {
	DEV_VIRTIO_GPIO_DIRECTION_NONE,
	DEV_VIRTIO_GPIO_DIRECTION_OUT,
	DEV_VIRTIO_GPIO_DIRECTION_IN
} dev_virtio_gpio_direction_t;

typedef enum {
	DEV_VIRTIO_GPIO_IRQ_TYPE_NONE,
	DEV_VIRTIO_GPIO_IRQ_TYPE_EDGE_RISING,
	DEV_VIRTIO_GPIO_IRQ_TYPE_EDGE_FALLING,
	DEV_VIRTIO_GPIO_IRQ_TYPE_EDGE_BOTH,
	DEV_VIRTIO_GPIO_IRQ_TYPE_LEVEL_HIGH,
	DEV_VIRTIO_GPIO_IRQ_TYPE_LEVEL_LOW,
} dev_virtio_irq_type_t;

/** @brief Callback handlers for gpio requests */
typedef struct {
	/** Get names of the GPIO lines */
	int (*get_names)(uint8_t *buffer, size_t len);

	/** Get direction of specified GPIO line */
	int (*get_direction)(unsigned int gpio, dev_virtio_gpio_direction_t *dir);

	/** Set direction of specified GPIO line */
	int (*set_direction)(unsigned int gpio, dev_virtio_gpio_direction_t dir);

	/** Get value of specified GPIO line */
	int (*get_value)(unsigned int gpio, unsigned int *value);

	/** Set value of specified GPIO line */
	int (*set_value)(unsigned int gpio, unsigned int value);

	/** Get type of IRQ tied to specified GPIO line */
	int (*set_irq_type)(unsigned int gpio, dev_virtio_irq_type_t type);

	/** Unmask IRQ tied to specified GPIO line */
	int (*unmask_irq)(unsigned int gpio, void *ctx, unsigned int ctx2);
} dev_virtio_gpio_cb_set;

/** @brief Representation of a gpio device based on virtio */
struct dev_virtio_gpio_device {
	/** Pointer to the virtio device */
	struct virtio_device *vdev;

	/** Pointer to request virtqueue */
	struct virtqueue *vq_request;

	/** Pointer to event virtqueue */
	struct virtqueue *vq_event;

	/** Callback handlers for gpio request */
	const dev_virtio_gpio_cb_set *callbacks;

	/** Mutex for callbacks */
	metal_mutex_t lock;
};

/**
 * @brief Send GPIO interrupt
 *
 * @param vgdev		Pointer to the GPIO virtio device
 * @param gpio		GPIO number
 * @param ctx		IRQ context as defined by unmask_irq()
 * @param ctx2		IRQ context as defined by unmask_irq()
 */
void dev_virtio_send_irq(struct dev_virtio_gpio_device *vgdev,
			 unsigned int gpio, void *ctx, unsigned int ctx2);

/**
 * @brief Initialize virtio GPIO device
 *
 * @param vgdev		Pointer to the GPIO virtio device
 * @param vdev		Pointer to the virtio device
 * @param shm_io	Pointer to the share memory I/O region.
 *
 * @return Status of function execution
 */
int dev_virtio_gpio_init_vdev(struct dev_virtio_gpio_device *vgdev,
			      struct virtio_device *vdev,
			      const dev_virtio_gpio_cb_set *callbacks,
			      struct metal_io_region *shm_io);

/**
 * @brief Deinitialize GPIO virtio device
 *
 * @param vgdev	Pointer to the gpio virtio device
 */
void dev_virtio_gpio_deinit_vdev(struct dev_virtio_gpio_device *vgdev);

#if defined __cplusplus
}
#endif

#endif	/* _DEV_VIRTIO_GPIO_H_ */
```

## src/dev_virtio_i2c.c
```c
/*
 * Virtio I2C device implementation
 *
 * Copyright (C) 2026 Francesco Valla
 *
 * SPDX-License-Identifier: Apache-2.0
 */

#include <metal/alloc.h>
#include <metal/mutex.h>
#include <metal/sleep.h>
#include <metal/sys.h>
#include <metal/utilities.h>

#include <openamp/virtqueue.h>
#include <openamp/remoteproc_virtio.h>

#include <zephyr/kernel.h>
#include <zephyr/device.h>
#include <zephyr/logging/log.h>
#include <zephyr/sys/byteorder.h>

#include "dev_virtio_common.h"
#include "dev_virtio_i2c.h"

#include "virtio_i2c.h"

LOG_MODULE_REGISTER(virtio_i2c, CONFIG_LOG_DEFAULT_LEVEL);

enum {
	I2C_REQ_OUT,
	I2C_REQ_BUF,
	I2C_REQ_IN,
	I2C_NUM_REQS
};

/**
 * @internal
 *
 * @brief Request callback function.
 *
 * @param vq	Pointer to virtqueue on which request is received
 */
static void dev_virtio_i2c_req_callback(struct virtqueue *vq)
{
	struct virtio_device *vdev = vq->vq_dev;
	struct dev_virtio_i2c_device *videv = vdev->priv;
	void *buf[I2C_NUM_REQS] = { NULL, NULL, NULL };
	uint16_t idx[I2C_NUM_REQS];
	uint32_t len[I2C_NUM_REQS];
	bool fail_next = false;
	bool last_failed = false;
	int ret;

	while (1) {
		/* Process the received data from remote node */
		metal_mutex_acquire(&videv->lock);

		buf[I2C_REQ_OUT] = virtqueue_get_first_avail_buffer(vq, &idx[I2C_REQ_OUT],
								    &len[I2C_REQ_OUT]);

		/* No more filled rx buffers */
		if (!buf[I2C_REQ_OUT]) {
			metal_mutex_release(&videv->lock);
			break;
		}

		/* Each request is composed by at least two parts */
		buf[I2C_REQ_BUF] = virtqueue_get_next_avail_buffer(vq, idx[I2C_REQ_OUT],
								   &idx[I2C_REQ_BUF],
								   &len[I2C_REQ_BUF]);
		if (!buf[I2C_REQ_BUF]) {
			virtqueue_add_consumed_buffer(vq, idx[I2C_REQ_OUT], 0);
			virtqueue_kick(vq);
			metal_mutex_release(&videv->lock);
			metal_log(METAL_LOG_ERROR, "i2c: not enough buffers");
			break;
		}

		/* A third part is there only for non-zero-length requests */
		buf[I2C_REQ_IN] = virtqueue_get_next_avail_buffer(vq, idx[I2C_REQ_BUF],
								  &idx[I2C_REQ_IN],
								  &len[I2C_REQ_IN]);
		if (!buf[I2C_REQ_IN]) {
			/* Treat the previous buffer as the IN one */
			buf[I2C_REQ_IN] = buf[I2C_REQ_BUF];
			buf[I2C_REQ_BUF] = NULL;

			len[I2C_REQ_IN] = len[I2C_REQ_BUF];
			len[I2C_REQ_BUF] = 0;
		}

		metal_mutex_release(&videv->lock);

		if (len[I2C_REQ_OUT] < sizeof(struct virtio_i2c_out_hdr)) {
			LOG_ERR("invalid out header length %u", len[I2C_REQ_OUT]);
		} else if (len[I2C_REQ_IN] < sizeof(struct virtio_i2c_in_hdr)) {
			LOG_ERR("invalid in header length %u", len[I2C_REQ_IN]);
		} else {
			const struct virtio_i2c_out_hdr *out;
			struct virtio_i2c_in_hdr *in;
			uint16_t addr;
			uint32_t flags;

			/* Invalidate cache before using buffer */
			BUFFER_INVALIDATE(buf[I2C_REQ_OUT], len[I2C_REQ_OUT]);

			out = (struct virtio_i2c_out_hdr *)buf[I2C_REQ_OUT];
			in = (struct virtio_i2c_in_hdr *)buf[I2C_REQ_IN];

			addr = sys_get_le16((const uint8_t *)&out->addr);
			flags = sys_get_le32((const uint8_t *)&out->flags);

			/* TODO: only 7-bit addressing is supported */
			addr >>= 1;

			/* Check if we are failing "next" requests */
			if (fail_next && last_failed) {
				LOG_INF("Forcibly failing next request");
				ret = -1;
			} else if (flags & VIRTIO_I2C_FLAGS_M_RD) {
				ret = videv->callbacks->read(addr, buf[I2C_REQ_BUF], len[I2C_REQ_BUF]);
				if (ret != 0)
					LOG_ERR("Read from %02Xh failed: %d", addr, ret);
			} else {
				ret = videv->callbacks->write(addr, buf[I2C_REQ_BUF], len[I2C_REQ_BUF]);
				if (ret != 0)
					LOG_ERR("Write to %02Xh failed: %d", addr, ret);
			}

			if (ret != 0) {
				last_failed = true;
				in->status = VIRTIO_I2C_MSG_ERR;
			} else {
				last_failed = false;
				in->status = VIRTIO_I2C_MSG_OK;
			}

			fail_next = !!(flags & VIRTIO_I2C_FLAGS_FAIL_NEXT);

			BUFFER_FLUSH(buf[I2C_REQ_IN], len[I2C_REQ_IN]);
			if (buf[I2C_REQ_BUF] != NULL)
				BUFFER_FLUSH(buf[I2C_REQ_BUF], len[I2C_REQ_BUF]);
		}

		metal_mutex_acquire(&videv->lock);

		ret = virtqueue_add_consumed_buffer(vq, idx[I2C_REQ_OUT],
						    len[I2C_REQ_IN] + len[I2C_REQ_BUF]);
		if (ret != 0)
			LOG_ERR("Add consumed buffer failed: %d", ret);

		virtqueue_kick(vq);

		metal_mutex_release(&videv->lock);
	}
}

int dev_virtio_i2c_init_vdev(struct dev_virtio_i2c_device *videv,
			     struct virtio_device *vdev,
			     const dev_virtio_i2c_cb_set *cb_set,
			     struct metal_io_region *shm_io)
{
	const char *vq_names[VIRTIO_I2C_VRINGS];
	vq_callback callbacks[VIRTIO_I2C_VRINGS];
	int status;

	if (!videv || !vdev || !cb_set || !shm_io)
		return -EINVAL;

	if (!cb_set->read || !cb_set->write)
		return -EINVAL;

	if (VIRTIO_ROLE_IS_DRIVER(vdev)) {
		return -ENOTSUP;
	}

	memset(videv, 0, sizeof(*videv));

	videv->vdev = vdev;
	videv->callbacks = cb_set;

	vdev->priv = videv;

	metal_mutex_init(&videv->lock);

	vq_names[0] = "requestq";
	callbacks[0] = dev_virtio_i2c_req_callback;

	/* Create virtqueues for remote device */
	status = virtio_create_virtqueues(vdev, 0, VIRTIO_I2C_VRINGS,
					  vq_names, callbacks, NULL);
	if (status != 0)
		return status;

	videv->vq_request = vdev->vrings_info[0].vq;
	videv->vq_request->shm_io = shm_io;

	return 0;
}

void dev_virtio_i2c_deinit_vdev(struct dev_virtio_i2c_device *videv)
{
	if (videv) {
		videv->vq_request = NULL;

		virtio_delete_virtqueues(videv->vdev);
		videv->vdev = NULL;

		metal_mutex_deinit(&videv->lock);
	}
}
```

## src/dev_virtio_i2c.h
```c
/*
 * Virtio I2C device implementation
 *
 * Copyright (C) 2026 Francesco Valla
 *
 * SPDX-License-Identifier: Apache-2.0
 */

#ifndef _DEV_VIRTIO_I2C_H_
#define _DEV_VIRTIO_I2C_H_

#include <metal/io.h>
#include <metal/mutex.h>
#include <metal/cache.h>

#include <openamp/virtio.h>

#define VIRTIO_I2C_VRINGS	1

#if defined __cplusplus
extern "C" {
#endif

/** @brief Callback handlers for i2c requests */
typedef struct {
	/** I2C read transaction */
	int (*read)(uint16_t addr, uint8_t *buffer, size_t len);

	/** I2C write transaction */
	int (*write)(uint16_t addr, const uint8_t *buffer, size_t len);
} dev_virtio_i2c_cb_set;

/** @brief Representation of a i2c device based on virtio */
struct dev_virtio_i2c_device {
	/** Pointer to the virtio device */
	struct virtio_device *vdev;

	/** Pointer to request virtqueue */
	struct virtqueue *vq_request;

	/** Callback handlers for i2c request */
	const dev_virtio_i2c_cb_set *callbacks;

	/** Mutex for callbacks */
	metal_mutex_t lock;
};

/**
 * @brief Initialize virtio I2C device
 *
 * @param videv		Pointer to the I2C virtio device
 * @param vdev		Pointer to the virtio device
 * @param callbacks	Pointer to set of callbacks
 * @param shm_io	Pointer to the share memory I/O region.
 *
 * @return Status of function execution
 */
int dev_virtio_i2c_init_vdev(struct dev_virtio_i2c_device *videv,
			     struct virtio_device *vdev,
			     const dev_virtio_i2c_cb_set *callbacks,
			     struct metal_io_region *shm_io);

/**
 * @brief Deinitialize I2C virtio device
 *
 * @param videv	Pointer to the i2c virtio device
 */
void dev_virtio_i2c_deinit_vdev(struct dev_virtio_i2c_device *videv);

#if defined __cplusplus
}
#endif

#endif	/* _DEV_VIRTIO_I2C_H_ */
```
